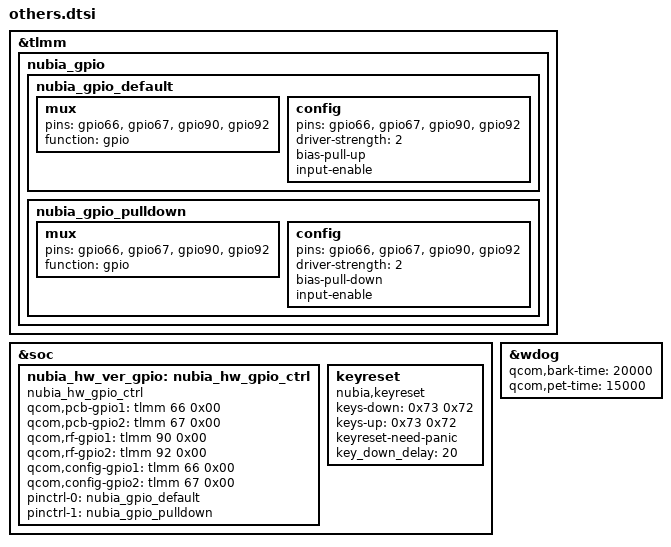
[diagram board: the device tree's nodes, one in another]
&tlmm {
        nubia_gpio {
                nubia_gpio_default: nubia_gpio_default {
                        mux {
                                pins = "gpio66", "gpio67", "gpio90", "gpio92";
                                function = "gpio";
                        };
                        config {
                                pins = "gpio66", "gpio67", "gpio90", "gpio92";
                                driver-strength = <2>; /* 2mA */
                                bias-pull-up;
                                input-enable;
                        };
                };

                nubia_gpio_pulldown: nubia_gpio_pulldown {
                        mux {
                                pins = "gpio66", "gpio67", "gpio90", "gpio92";
                                function = "gpio";
                        };
                        config {
                                pins = "gpio66", "gpio67", "gpio90", "gpio92";
                                driver-strength = <2>; /* 2mA */
                                bias-pull-down;
                                input-enable;
                        };
                };
        };
};
&soc {
        nubia_hw_ver_gpio: nubia_hw_gpio_ctrl {
                compatible = "nubia_hw_gpio_ctrl";
                qcom,pcb-gpio1 = <&tlmm 66 0x00>;
                qcom,pcb-gpio2 = <&tlmm 67 0x00>;
                qcom,rf-gpio1 = <&tlmm 90 0x00>;
                qcom,rf-gpio2 = <&tlmm 92 0x00>;
                qcom,config-gpio1 = <&tlmm 66 0x00>;
                qcom,config-gpio2 = <&tlmm 67 0x00>;
                pinctrl-names = "pull_up_default","pull_down_default";
                pinctrl-0 = <&nubia_gpio_default>;
                pinctrl-1 = <&nubia_gpio_pulldown>;
        };
	keyreset {
		compatible = "nubia,keyreset";
		keys-down = <0x73 0x72>;
		keys-up = <0x73 0x72>;
		keyreset-need-panic;
		key_down_delay = <20>;
	};
};

&wdog {
        qcom,bark-time = <20000>;
        qcom,pet-time = <15000>;
};
